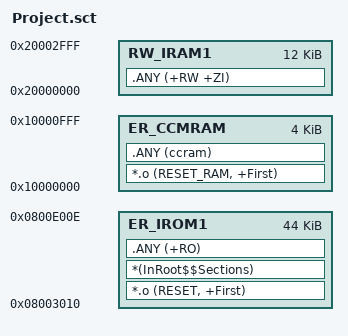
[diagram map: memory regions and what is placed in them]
; *************************************************************
; *** Scatter-Loading Description File generated by uVision ***
; *************************************************************

; w/o boot loader
;LR_IROM1 0x08000000 0x000057FF  {    ; load region size_region
;  ER_IROM1 0x08000000 0x000057FF  {  ; load address = execution address

; 32kB Flash
;LR_IROM1 0x08002010 0x000077FF  {    ; load region size_region
;  ER_IROM1 0x08002010 0x000077FF  {  ; load address = execution address

; 64kB Flash
LR_IROM1 0x08003010 0x0000AFFF  {    ; load region size_region
  ER_IROM1 0x08003010 0x0000AFFF  {  ; load address = execution address

   *.o (RESET, +First)
   *(InRoot$$Sections)
   .ANY (+RO)
  }
  RW_IRAM1 0x20000000 0x00003000  {  ; RW data
   .ANY (+RW +ZI)
  }
  ER_CCMRAM 0x10000000 0x00001000  {
   *.o (RESET_RAM, +First)
   .ANY (ccram)
  }
}

